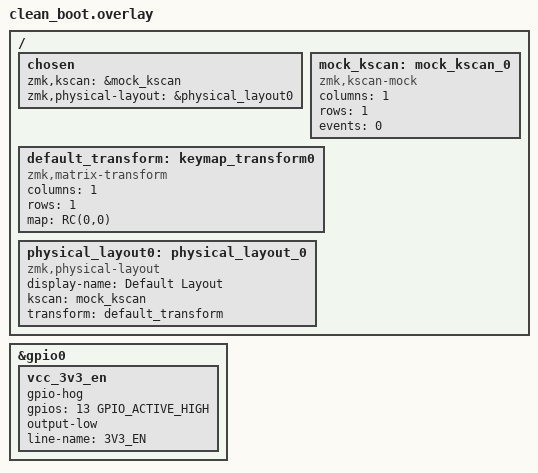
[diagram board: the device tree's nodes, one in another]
#include <zephyr/dt-bindings/gpio/gpio.h>
#include <dt-bindings/zmk/matrix_transform.h>

/ {
    chosen {
        zmk,kscan = &mock_kscan;
        zmk,physical-layout = &physical_layout0;
    };

    mock_kscan: mock_kscan_0 {
        compatible = "zmk,kscan-mock";
        columns = <1>;
        rows = <1>;
        events = <0>;
    };

    default_transform: keymap_transform0 {
        compatible = "zmk,matrix-transform";
        columns = <1>;
        rows = <1>;
        map = <RC(0,0)>;
    };

    physical_layout0: physical_layout_0 {
        compatible = "zmk,physical-layout";
        display-name = "Default Layout";
        kscan = <&mock_kscan>;
        transform = <&default_transform>;
    };
};

&gpio0 {
    vcc_3v3_en: vcc_3v3_en {
        gpio-hog;
        gpios = <13 GPIO_ACTIVE_HIGH>;
        output-low;
        line-name = "3V3_EN";
    };
};
